# STM32MP21_CM33 register map
File version: 0.4
CPU: CM33 r0p1, little endian, MPU, FPU, vendor SysTick, 8 interrupt priority bits
Registers are 32-bit, read-write, reset 0x0 unless marked. A register's access mark holds for its fields unless they carry their own. Offsets are from the block's base; [hi:lo] are bit positions; {n}, {i} and the like mark numbered series.

## HASH1 — HASH register bank
Base 0x42030400
Same registers: HASH2 0x42010000, HASH2_S 0x52010000, HASH1_S 0x52030400
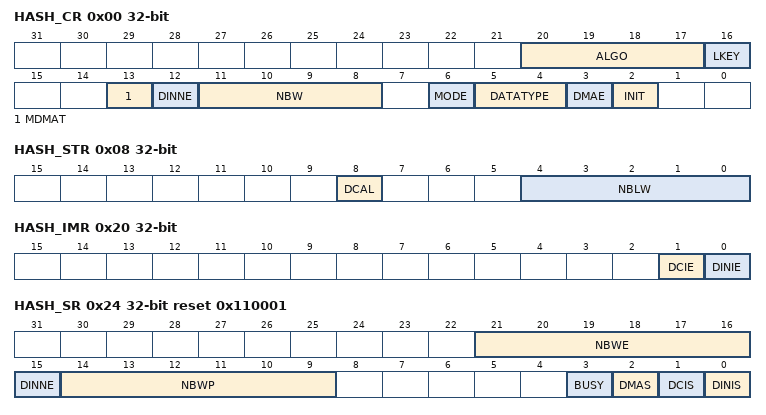
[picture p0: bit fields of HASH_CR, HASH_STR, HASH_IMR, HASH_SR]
0x00 HASH_CR — HASH control register
  [20:17] ALGO — Algorithm selection
    0=SHA-1; 2=SHA2-224; 3=SHA2-256; 12=SHA2-384; 13=SHA2-512/224; 14=SHA2-512/256; 15=SHA2-512; 4=SHA3-224; 5=SHA3-256; 6=SHA3-384; 7=SHA3-512; 8=SHAKE128; 9=SHAKE256
  [16] LKEY — Long key selection
    0=HMAC key is shorter or equal to the block size (short key); 1=HMAC key is longer than the block size (long key)
  [13] MDMAT — Multiple DMA transfers
    0=DCAL is automatically set at the end of a DMA transfer; 1=DCAL is not automatically set at the end of a DMA transfer
  [12] DINNE ro — DIN not empty
  [11:8] NBW ro — Number of words already pushed
  [6] MODE — Mode selection
    0=Hash mode selected; 1=HMAC mode selected
  [5:4] DATATYPE — Data type selection
    0=32-bit data; 1=16-bit data or half-word; 2=8-bit data or bytes; 3=bit data or bit string
  [3] DMAE — DMA enable
    0=DMA transfers disabled; 1=DMA transfers enabled
  [2] INIT — Initialize message digest calculation
0x04 HASH_DIN wo — HASH data input register
  [31:0] DATAIN — Data input
0x08 HASH_STR — HASH start register
  [8] DCAL — Digest calculation
  [4:0] NBLW — Number of valid bits in the last word
    0=All the 32 bits of the last data written are valid message bits, that is M[31:0]; 1=Only one bit of the last data written (after swapping) is valid, that is M[0]; 2=Only two bits of the last data written (after swapping) are valid, that is M[1:0]; 3=Only three bits of the last data written (after swapping) are valid that is M[2:0]; 31=Only 31 bits of the last data written (after swapping) are valid that is M[30:0]
{0xC+4i} HASH_HRA{i} ro (i=0..4) — HASH aliased digest register {i}
  [31:0] H{i} — Hash data x
0x20 HASH_IMR — HASH interrupt enable register
  [1] DCIE — Digest calculation completion interrupt enable
    0=Digest calculation completion interrupt disabled; 1=Digest calculation completion interrupt enabled
  [0] DINIE — Data input interrupt enable
    0=Data input interrupt disabled; 1=Data input interrupt enabled
0x24 HASH_SR reset 0x110001 — HASH status register
  [21:16] NBWE ro — Number of words expected
  [15] DINNE ro — DIN not empty
    0=No data are present in the data input buffer; 1=The input buffer contains at least one word of data
  [14:9] NBWP ro — Number of words already pushed
  [3] BUSY ro — Busy bit
    0=No block is currently being processed; 1=The hash core is processing a block of data
  [2] DMAS ro — DMA Status
    0=DMA interface is disabled (DMAE=0) and no transfer is ongoing; 1=DMA interface is enabled (DMAE=1) or a transfer is ongoing
  [1] DCIS — Digest calculation completion interrupt status
    0=No digest available in the HASH_HRx registers (zeros are returned); 1=Digest calculation complete, a digest is available in the HASH_HRx registers
  [0] DINIS — Data input interrupt status
    0=Less than 16 locations are free in the input buffer; 1=A new block can be entered into the input buffer
{0xF8+4i} HASH_CSR{i} (i=0..102) — HASH context swap register {i}
  [31:0] CS{i} — Context swap x
{0x310+4i} HASH_HR{i} ro (i=0..4) — HASH digest register {i}
  [31:0] H{i} — Hash data x
{0x310+4i} HASH_HR{i} ro (i=5..41) — HASH supplementary digest register {i}
  [31:0] H{i} — Hash data x
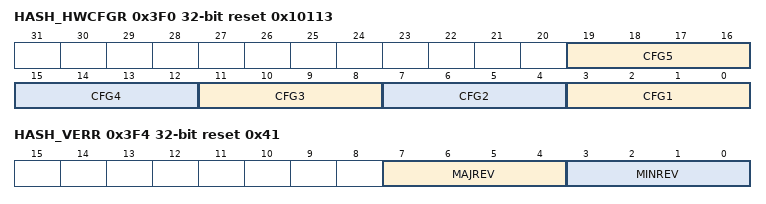
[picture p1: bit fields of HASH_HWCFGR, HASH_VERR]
0x3F0 HASH_HWCFGR ro reset 0x10113 — HASH hardware configuration register
  [4n-1:4n-4] CFG{n} (n=1..5) — HW generic {n}
0x3F4 HASH_VERR ro reset 0x41 — HASH version register
  [7:4] MAJREV — Major revision
  [3:0] MINREV — Minor revision
0x3F8 HASH_IPIDR ro reset 0x170031 — HASH identification register
  [31:0] ID — Identifier
0x3FC HASH_SIDR ro reset 0xA3C5DD01 — HASH size identification register
  [31:0] SID — Size identification code
